# ATSAM4C16C_1 device description
Architecture: CORTEX-M4; Family: SAM4; Series: SAM4C
Registers are 32-bit, read-write, no defined reset value unless marked. A register's access mark holds for its fields unless they carry their own. Offsets are from the block's base; [hi:lo] are bit positions; {n}, {i} and the like mark numbered series; 'fields as' and 'values as' point back to an identical list.

## IPC — Interprocessor Communication
Instances: IPC0 0x4004C000, IPC1 0x48014000
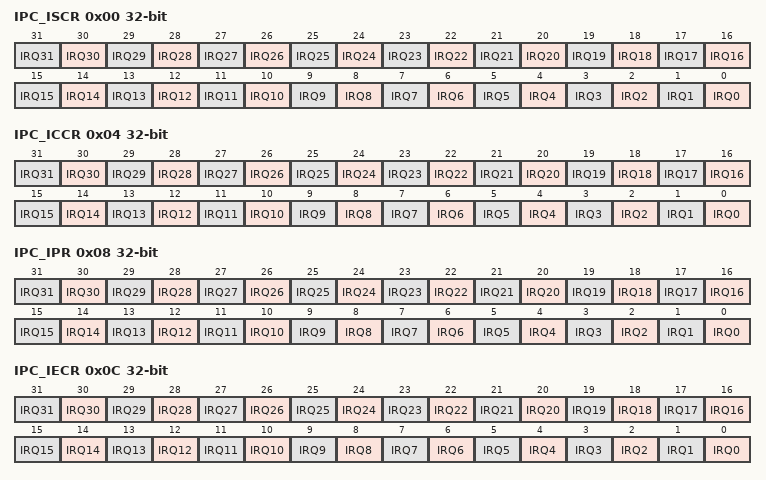
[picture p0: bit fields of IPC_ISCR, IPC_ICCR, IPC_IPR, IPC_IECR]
0x00 IPC_ISCR wo — Interrupt Set Command Register
  [n] IRQ{n} (n=0..31) — Interrupt Set
0x04 IPC_ICCR wo — Interrupt Clear Command Register
  [n] IRQ{n} (n=0..31) — Interrupt Clear
0x08 IPC_IPR ro — Interrupt Pending Register
  [n] IRQ{n} (n=0..31) — Interrupt Pending
0x0C IPC_IECR wo — Interrupt Enable Command Register
  [n] IRQ{n} (n=0..31) — Interrupt Enable
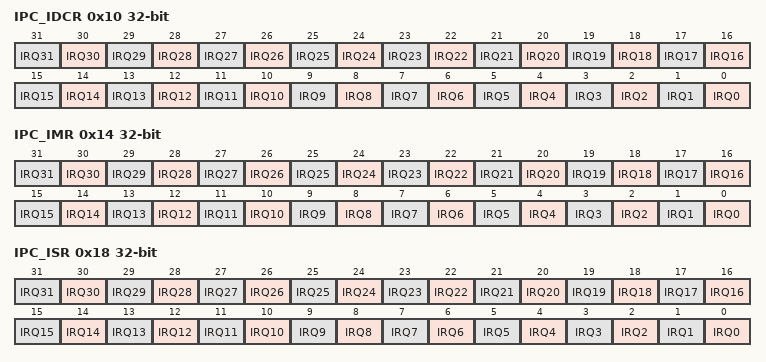
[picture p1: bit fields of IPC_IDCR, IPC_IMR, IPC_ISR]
0x10 IPC_IDCR wo — Interrupt Disable Command Register
  [n] IRQ{n} (n=0..31) — Interrupt Disable
0x14 IPC_IMR ro — Interrupt Mask Register
  [n] IRQ{n} (n=0..31) — Interrupt Mask
0x18 IPC_ISR ro — Interrupt Status Register
  [n] IRQ{n} (n=0..31) — Current Interrupt Identifier

## MATRIX — AHB Bus Matrix
Instances: MATRIX0 0x400E0200, MATRIX1 0x48010000
{0x0+4i} MATRIX_MCFG{i} (i=0..7) — Master Configuration Register {i}
  [2:0] ULBT — Undefined Length Burst Type
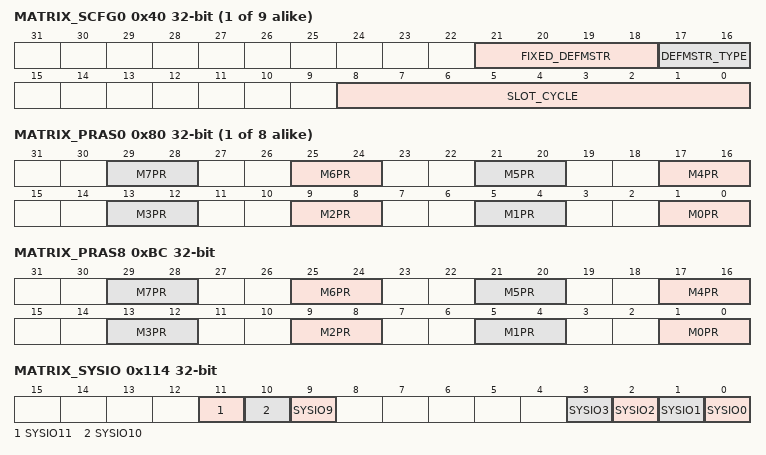
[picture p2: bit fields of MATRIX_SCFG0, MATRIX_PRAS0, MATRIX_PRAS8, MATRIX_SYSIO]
{0x40+4i} MATRIX_SCFG{i} (i=0..8) — Slave Configuration Register {i}
  [21:18] FIXED_DEFMSTR — Fixed Default Master
  [17:16] DEFMSTR_TYPE — Default Master Type
  [8:0] SLOT_CYCLE — Maximum Bus Grant Duration for Masters
{0x80+8i} MATRIX_PRAS{i} (i=0..7) — Priority Register A for Slave {i}
  [4n+1:4n] M{n}PR (n=0..7) — Master {n} Priority
0xBC MATRIX_PRAS8 — Priority Register A for Slave 8
  [4n+1:4n] M{n}PR (n=0..7) — Master {n} Priority
0x114 MATRIX_SYSIO — System I/O Configuration Register
  [11] SYSIO11 — PD1 or DDP Assignment
  [10] SYSIO10 — PD0 or DDM Assignment
  [9] SYSIO9 — PC9 or ERASE Assignment
  [3] SYSIO3 — PB3 or TCK/SWCLK Assignment
  [2] SYSIO2 — PB2 or TMS/SWDIO Assignment
  [1] SYSIO1 — PB1 or TDO/TRACESWO Assignment
  [0] SYSIO0 — PB0 or TDI Assignment
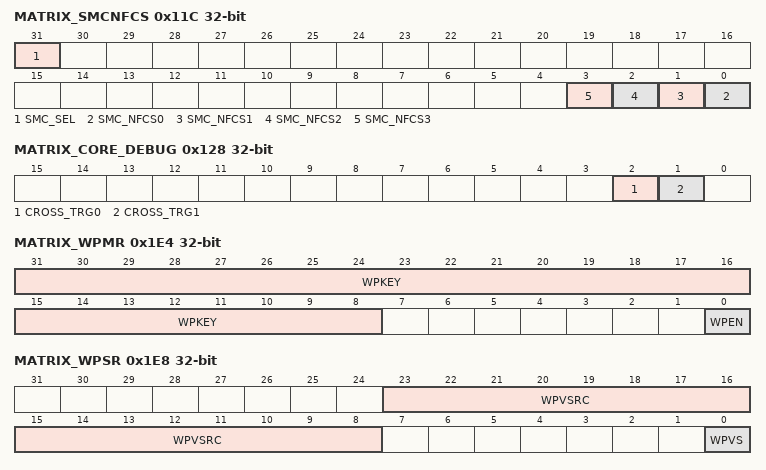
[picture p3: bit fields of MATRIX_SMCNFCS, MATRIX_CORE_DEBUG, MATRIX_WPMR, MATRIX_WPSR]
0x11C MATRIX_SMCNFCS — SMC Nand Flash Chip Select Configuration Register
  [31] SMC_SEL — SMC Selection for EBI pins
  [n] SMC_NFCS{n} (n=0..3) — SMC NAND Flash Chip Select {n} Assignment
0x128 MATRIX_CORE_DEBUG — Core Debug Configuration Register
  [2] CROSS_TRG0, [1] CROSS_TRG1
0x1E4 MATRIX_WPMR — Write Protection Mode Register
  [31:8] WPKEY — Write Protect Key
    0x4D4154=PASSWD (Writing any other value in this field aborts the write operation of the WPEN bit.Always reads as 0.)
  [0] WPEN — Write Protect Enable
0x1E8 MATRIX_WPSR ro — Write Protection Status Register
  [23:8] WPVSRC — Write Protection Violation Source
  [0] WPVS — Write Protection Violation Status

## PDC — Peripheral DMA Controller
0x00 PERIPH_RPR — Receive Pointer Register
  [31:0] RXPTR
0x04 PERIPH_RCR — Receive Counter Register
  [15:0] RXCTR
0x08 PERIPH_TPR — Transmit Pointer Register
  [31:0] TXPTR — Transmit Counter Register
0x0C PERIPH_TCR — Transmit Counter Register
  [15:0] TXCTR
0x10 PERIPH_RNPR — Receive Next Pointer Register
  [31:0] RXNPTR — Receive Next Pointer
0x14 PERIPH_RNCR — Receive Next Counter Register
  [15:0] RXNCTR — Receive Next Counter
0x18 PERIPH_TNPR — Transmit Next Pointer Register
  [31:0] TXNPTR — Transmit Next Pointer
0x1C PERIPH_TNCR — Transmit Next Counter Register
  [15:0] TXNCTR — Transmit Counter Next
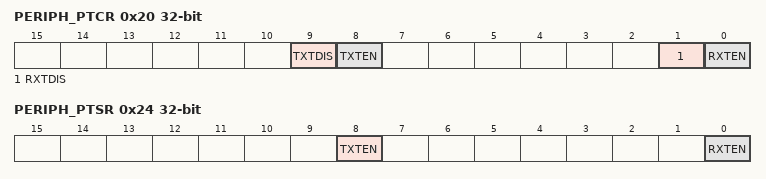
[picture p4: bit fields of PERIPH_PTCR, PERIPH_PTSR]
0x20 PERIPH_PTCR wo — Transfer Control Register
  [9] TXTDIS — Transmitter Transfer Disable
  [8] TXTEN — Transmitter Transfer Enable
  [1] RXTDIS — Receiver Transfer Disable
  [0] RXTEN — Receiver Transfer Enable
0x24 PERIPH_PTSR ro — Transfer Status Register
  [8] TXTEN — Transmitter Transfer Enable
  [0] RXTEN — Receiver Transfer Enable

## PWM — Pulse Width Modulation Controller
Instances: PWM 0x48008000
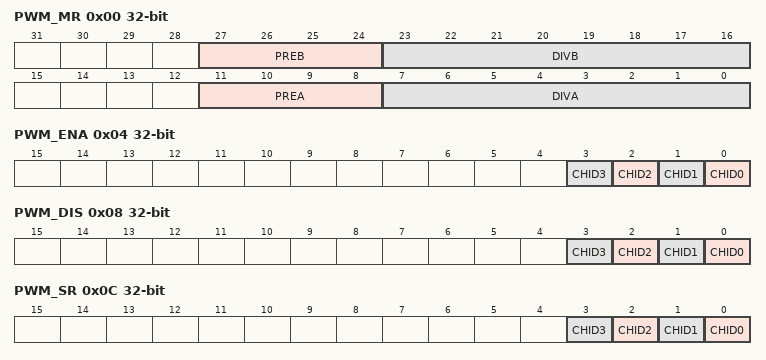
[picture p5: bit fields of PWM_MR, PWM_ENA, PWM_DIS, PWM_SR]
0x00 PWM_MR — PWM Mode Register
  [27:24] PREB
    0=MCK (Master Clock); 1=MCKDIV2 (Master Clock divided by 2); 2=MCKDIV4 (Master Clock divided by 4); 3=MCKDIV8 (Master Clock divided by 8); 4=MCKDIV16 (Master Clock divided by 16); 5=MCKDIV32 (Master Clock divided by 32); 6=MCKDIV64 (Master Clock divided by 64); 7=MCKDIV128 (Master Clock divided by 128); 8=MCKDIV256 (Master Clock divided by 256); 9=MCKDIV512 (Master Clock divided by 512); 10=MCKDIV1024 (Master Clock divided by 1024)
  [23:16] DIVB — CLKA, CLKB Divide Factor
    0=CLK_OFF (CLKA, CLKB clock is turned off); 1=CLK_DIV1 (CLKA, CLKB clock is clock selected by PREA, PREB)
  [11:8] PREA
    values as PREB
  [7:0] DIVA — CLKA, CLKB Divide Factor
    values as DIVB
0x04 PWM_ENA wo — PWM Enable Register
  [n] CHID{n} (n=0..3) — Channel ID
0x08 PWM_DIS wo — PWM Disable Register
  [n] CHID{n} (n=0..3) — Channel ID
0x0C PWM_SR ro — PWM Status Register
  [n] CHID{n} (n=0..3) — Channel ID
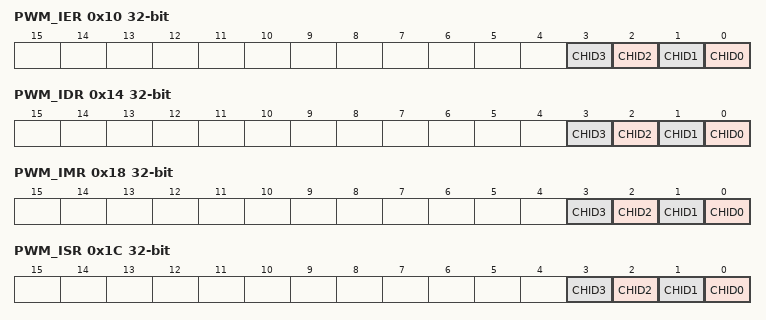
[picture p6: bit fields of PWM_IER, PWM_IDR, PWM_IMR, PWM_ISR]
0x10 PWM_IER wo — PWM Interrupt Enable Register
  [n] CHID{n} (n=0..3) — Channel ID.
0x14 PWM_IDR wo — PWM Interrupt Disable Register
  [n] CHID{n} (n=0..3) — Channel ID.
0x18 PWM_IMR ro — PWM Interrupt Mask Register
  [n] CHID{n} (n=0..3) — Channel ID.
0x1C PWM_ISR ro — PWM Interrupt Status Register
  [n] CHID{n} (n=0..3) — Channel ID
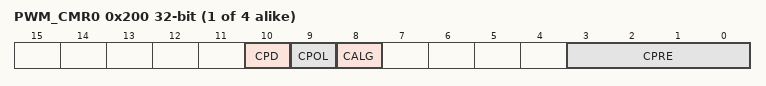
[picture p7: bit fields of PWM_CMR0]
{0x200+0x20*i} PWM_CMR{i} (i=0..3) — PWM Channel Mode Register (ch_num = {i})
  [10] CPD — Channel Update Period
  [9] CPOL — Channel Polarity
  [8] CALG — Channel Alignment
  [3:0] CPRE — Channel Pre-scaler
    0=MCK (Master Clock); 1=MCKDIV2 (Master Clock divided by 2); 2=MCKDIV4 (Master Clock divided by 4); 3=MCKDIV8 (Master Clock divided by 8); 4=MCKDIV16 (Master Clock divided by 16); 5=MCKDIV32 (Master Clock divided by 32); 6=MCKDIV64 (Master Clock divided by 64); 7=MCKDIV128 (Master Clock divided by 128); 8=MCKDIV256 (Master Clock divided by 256); 9=MCKDIV512 (Master Clock divided by 512); 10=MCKDIV1024 (Master Clock divided by 1024); 11=CLKA (Clock A); 12=CLKB (Clock B)
{0x204+0x20*i} PWM_CDTY{i} (i=0..3) — PWM Channel Duty Cycle Register (ch_num = {i})
  [31:0] CDTY — Channel Duty Cycle
{0x208+0x20*i} PWM_CPRD{i} (i=0..3) — PWM Channel Period Register (ch_num = {i})
  [31:0] CPRD — Channel Period
{0x20C+0x20*i} PWM_CCNT{i} ro (i=0..3) — PWM Channel Counter Register (ch_num = {i})
  [31:0] CNT — Channel Counter Register
{0x210+0x20*i} PWM_CUPD{i} wo (i=0..3) — PWM Channel Update Register (ch_num = {i})
  [31:0] CUPD

## Notices in the file
SAM Software Package License
Copyright (c) %copyright_year%, Atmel Corporation
All rights reserved.
Redistribution and use in source and binary forms, with or without
modification, are permitted provided that the following condition is met:
- Redistributions of source code must retain the above copyright notice,
this list of conditions and the disclaimer below.
Atmel's name may not be used to endorse or promote products derived from
this software without specific prior written permission.
DISCLAIMER:  THIS SOFTWARE IS PROVIDED BY ATMEL "AS IS" AND ANY EXPRESS OR
IMPLIED WARRANTIES, INCLUDING, BUT NOT LIMITED TO, THE IMPLIED WARRANTIES OF
MERCHANTABILITY, FITNESS FOR A PARTICULAR PURPOSE AND NON-INFRINGEMENT ARE
DISCLAIMED. IN NO EVENT SHALL ATMEL BE LIABLE FOR ANY DIRECT, INDIRECT,
INCIDENTAL, SPECIAL, EXEMPLARY, OR CONSEQUENTIAL DAMAGES (INCLUDING, BUT NOT
LIMITED TO, PROCUREMENT OF SUBSTITUTE GOODS OR SERVICES; LOSS OF USE, DATA,
OR PROFITS; OR BUSINESS INTERRUPTION) HOWEVER CAUSED AND ON ANY THEORY OF
LIABILITY, WHETHER IN CONTRACT, STRICT LIABILITY, OR TORT (INCLUDING
NEGLIGENCE OR OTHERWISE) ARISING IN ANY WAY OUT OF THE USE OF THIS SOFTWARE,
EVEN IF ADVISED OF THE POSSIBILITY OF SUCH DAMAGE.
